# PT32x002xx register map
File version: 0.2
Registers are 32-bit, read-write, reset 0x0 unless marked. A register's access mark holds for its fields unless they carry their own. Offsets are from the block's base; [hi:lo] are bit positions; {n}, {i} and the like mark numbered series.

## SYSCFG — System Configuration
Base 0x40020C00
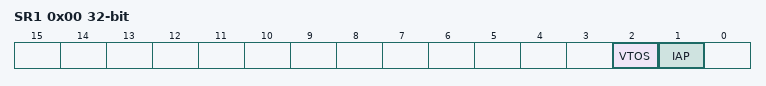
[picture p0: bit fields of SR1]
0x00 SR1 — Status Register 1
  [2] VTOS — Interrupt vector table location selection flag
  [1] IAP ro — IAP enable flag
0x14 IAPAR ro — IAP Address Register
  [31:0] ADDR — IAP address
0x18 SVTOR — SRAM Interrupt Vector Table Address Register
  [31:0] ADDR — SRAM interrupt vector table address

## GPIOA — General purpose I/O
Base 0x48000000
Same registers: GPIOB 0x48001000
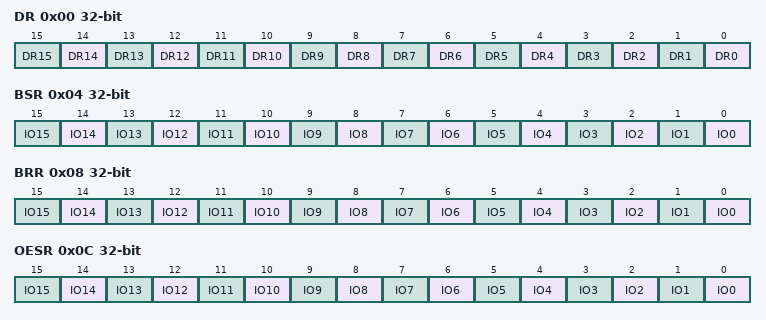
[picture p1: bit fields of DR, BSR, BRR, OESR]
0x00 DR — Port Data Register
  [n] DR{n} (n=0..15) — Port x pin {n} data
0x04 BSR wo — Port Bit Set Register
  [n] IO{n} (n=0..15) — Port x set bit {n}
0x08 BRR wo — Port Bit Reset Register
  [n] IO{n} (n=0..15) — Port x reset bit {n}
0x0C OESR — Output Enable Set Register
  [n] IO{n} (n=0..15) — Port x pin {n} output enable
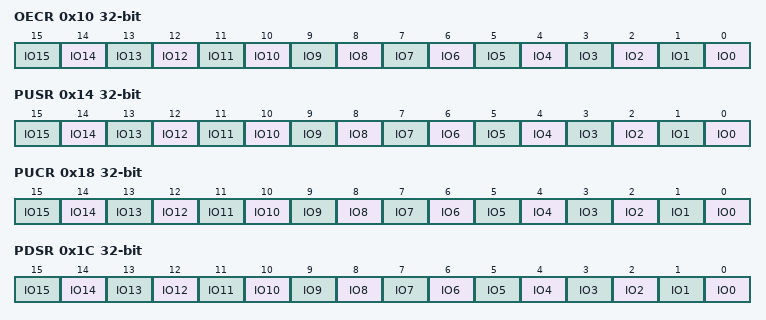
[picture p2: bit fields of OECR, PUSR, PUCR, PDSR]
0x10 OECR wo — Output Enable Clear Register
  [n] IO{n} (n=0..15) — Port x pin {n} output disable
0x14 PUSR — Pull-Up Set Register
  [n] IO{n} (n=0..15) — Port x pin {n} input pull-up enable
0x18 PUCR wo — Pull-Up Clear Register
  [n] IO{n} (n=0..15) — Port x pin {n} input pull-up disable
0x1C PDSR — Pull-Down Set Register
  [n] IO{n} (n=0..15) — Port x pin {n} input pull-down enable
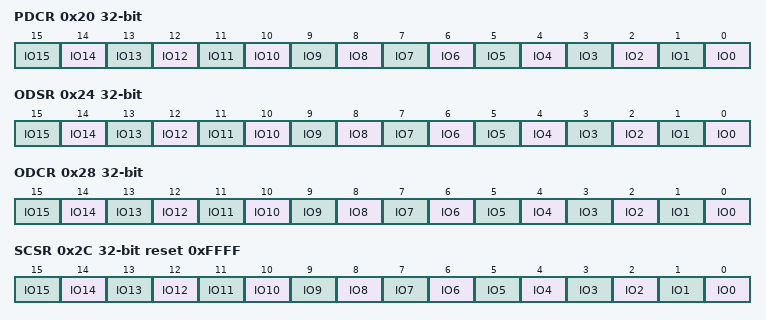
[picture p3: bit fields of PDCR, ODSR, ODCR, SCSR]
0x20 PDCR wo — Pull-Down Clear Register
  [n] IO{n} (n=0..15) — Port x pin {n} input pull-down disable
0x24 ODSR — Output Open-Drain Set Register
  [n] IO{n} (n=0..15) — Port x pin {n} output open-drain enable
0x28 ODCR wo — Output Open-Drain Clear Register
  [n] IO{n} (n=0..15) — Port x pin {n} output open-drain disable
0x2C SCSR reset 0xFFFF — Input Schmitt Set Register
  [n] IO{n} (n=0..15) — Port x pin {n} input Schmitt trigger enable
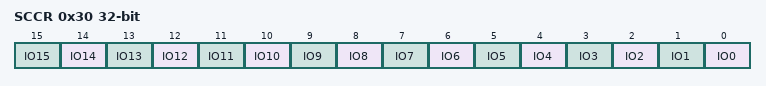
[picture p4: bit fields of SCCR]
0x30 SCCR wo — Input Schmitt Clear Register
  [n] IO{n} (n=0..15) — Port x pin {n} input Schmitt trigger disable

## AFIOA — Alternate function
Base 0x48000100
Same registers: AFIOB 0x48001100
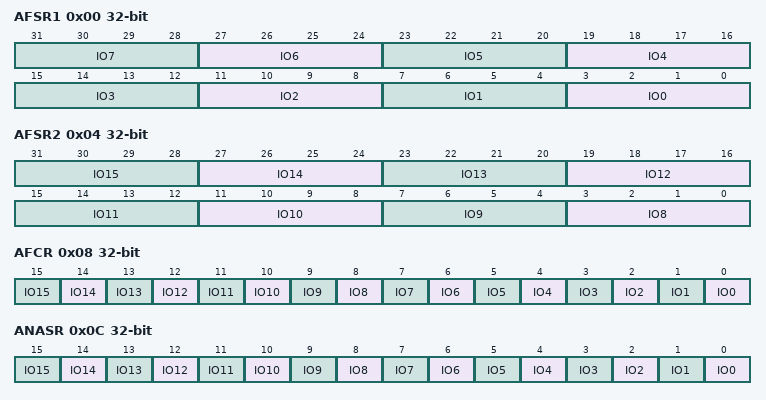
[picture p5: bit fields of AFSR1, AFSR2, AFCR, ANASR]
0x00 AFSR1 — Digtal Alternate Function Set Register 1
  [4n+3:4n] IO{n} (n=0..7) — Port x pin {n} digtal alternate function
0x04 AFSR2 — Digtal Alternate Function Set Register 2
  [4n-29:4n-32] IO{n} (n=8..15) — Port x pin {n} digtal alternate function
0x08 AFCR wo — Digtal Alternate Function Clear Register
  [n] IO{n} (n=0..15) — Port x pin {n} digtal alternate function clear
0x0C ANASR — Analog Alternate Function Set Register
  [n] IO{n} (n=0..15) — Port x pin {n} analog alternate function
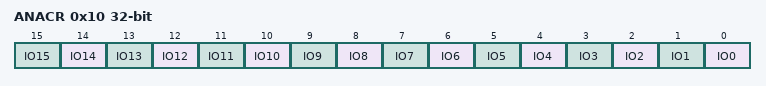
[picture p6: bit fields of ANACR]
0x10 ANACR wo — Analog Alternate Function Clear Register
  [n] IO{n} (n=0..15) — Port x pin {n} analog alternate function clear

## EXTIA — External interrupt
Base 0x48000200
Same registers: EXTIB 0x48001200
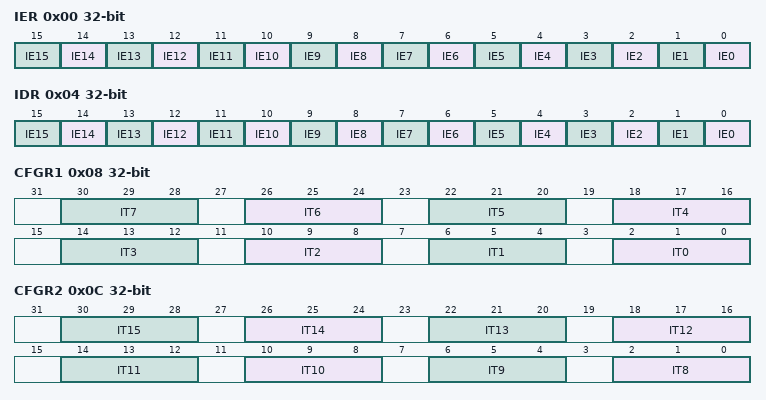
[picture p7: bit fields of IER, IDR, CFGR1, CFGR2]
0x00 IER — Interrupt Enable Register
  [n] IE{n} (n=0..15) — port x pin {n} input interrupt enable
0x04 IDR wo — Interrupt Disable Register
  [n] IE{n} (n=0..15) — port x pin {n} input interrupt disable
0x08 CFGR1 — Interrupt Type Configuration Register 1
  [4n+2:4n] IT{n} (n=0..7) — port x pin {n} input interrupt type
0x0C CFGR2 — Interrupt Type Configuration Register2
  [4n-30:4n-32] IT{n} (n=8..15) — port x pin {n} input interrupt type
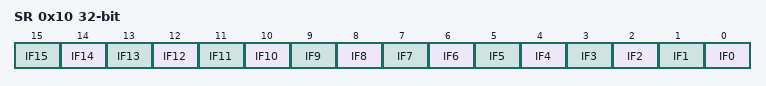
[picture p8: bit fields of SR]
0x10 SR — Interrupt Status Register
  [n] IF{n} (n=0..15) — port x pin {n} input interrupt flag

## ADC — Analog-to-digital converters
Base 0x40012400
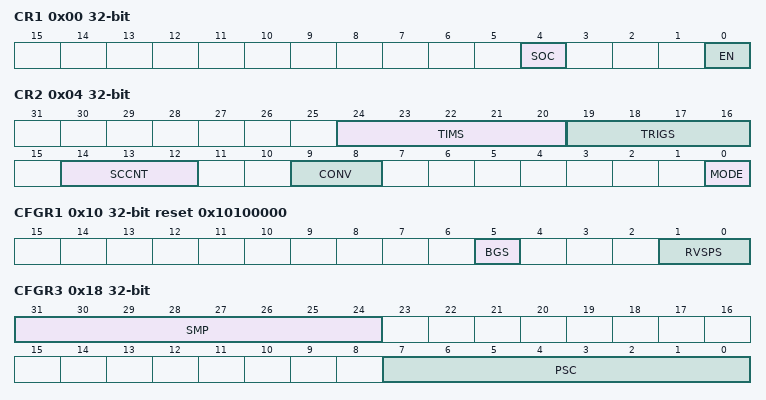
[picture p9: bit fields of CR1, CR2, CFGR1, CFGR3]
0x00 CR1 access per field — Control Register 1
  [4] SOC wo — ADC start on control
  [0] EN rw — ADC enable
0x04 CR2 — Control Register 2
  [24:20] TIMS — ADC regular timer trigger source selection
  [19:16] TRIGS — ADC regular trigger source selection
  [14:12] SCCNT — Single conversion count control
  [9:8] CONV — ADC conversion control
  [0] MODE — ADC regular conversion mode
0x10 CFGR1 access per field reset 0x10100000 — Configuration Register 1
  [5] BGS ro — BGREF source selection
  [1:0] RVSPS rw — Reference voltage source positive selection
0x14 CFGR2 — Configuration Register 2
  [21:16] CHS — ADC channel selection
0x18 CFGR3 — Configuration Register 3
  [31:24] SMP — ADC sample time
  [7:0] PSC — ADC prescaler
0x1C IER — Interrupt Enable Register
  [1] EOCIE — ADC end of conversion interrupt enable
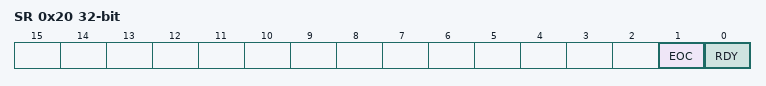
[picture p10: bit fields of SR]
0x20 SR ro — Status Register
  [1] EOC — ADC end of conversion
  [0] RDY — ADC ready
0x30 DR ro — Data Register
  [15:0] DATA — ADC data
